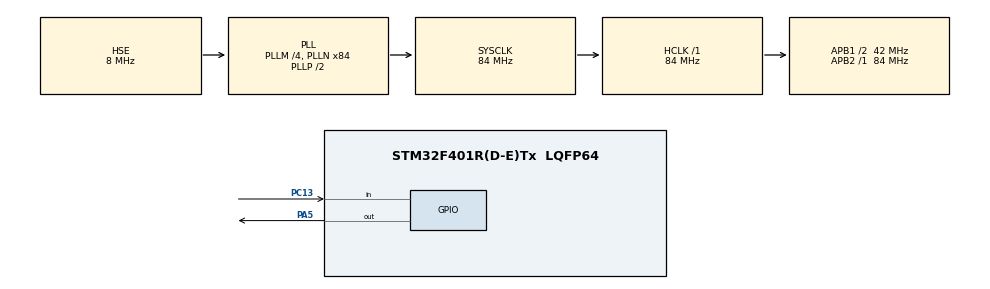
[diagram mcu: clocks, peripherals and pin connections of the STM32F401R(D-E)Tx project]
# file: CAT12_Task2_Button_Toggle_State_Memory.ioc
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Mcu.Family=STM32F4
Mcu.Name=STM32F401R(D-E)Tx
Mcu.Package=LQFP64
NVIC.PriorityGroup=NVIC_PRIORITYGROUP_4
PA13.Mode=Serial_Wire
PA13.Signal=SYS_JTMS-SWDIO
PA14.Mode=Serial_Wire
PA14.Signal=SYS_JTCK-SWCLK
PA5.Signal=GPIO_Output
PC13-ANTI_TAMP.GPIO_PuPd=GPIO_PULLUP
PC13-ANTI_TAMP.Signal=GPIO_Input
PH0\ -\ OSC_IN.Mode=HSE-External-Clock-Source
PH0\ -\ OSC_IN.Signal=RCC_OSC_IN
PH1\ -\ OSC_OUT.Mode=HSE-External-Clock-Source
PH1\ -\ OSC_OUT.Signal=RCC_OSC_OUT
ProjectManager.HeapSize=0x200
ProjectManager.StackSize=0x400
ProjectManager.TargetToolchain=STM32CubeIDE
RCC.48MHZClocksFreq_Value=42000000
RCC.AHBFreq_Value=84000000
RCC.APB1CLKDivider=RCC_HCLK_DIV2
RCC.APB1Freq_Value=42000000
RCC.APB1TimFreq_Value=84000000
RCC.APB2Freq_Value=84000000
RCC.APB2TimFreq_Value=84000000
RCC.CortexFreq_Value=84000000
RCC.HCLKFreq_Value=84000000
RCC.HSE_VALUE=8000000
RCC.HSI_VALUE=16000000
RCC.LSE_VALUE=32768
RCC.PLLM=4
RCC.PLLN=84
RCC.PLLSourceVirtual=RCC_PLLSOURCE_HSE
RCC.SYSCLKFreq_VALUE=84000000
RCC.SYSCLKSource=RCC_SYSCLKSOURCE_PLLCLK
RCC.VCOOutputFreq_Value=168000000
board=custom

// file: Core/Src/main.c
/* USER CODE BEGIN Header */
/**
  ******************************************************************************
  * @file           : main.c
  * @brief          : CAT 12 - Task 2 : B1 toggles LD2 and the LED remembers its state
  *                    Debounced press-edge detection, no blocking delays.
  ******************************************************************************
  * @attention
  *
  * Copyright (c) 2026 STMicroelectronics.
  * All rights reserved.
  *
  * This software is licensed under terms that can be found in the LICENSE file
  * in the root directory of this software component.
  * If no LICENSE file comes with this software, it is provided AS-IS.
  *
  ******************************************************************************
  */
/* USER CODE END Header */
#include "main.h"

/* USER CODE BEGIN PTD */
typedef struct
{
  uint8_t  stable;        /* debounced level, 1 = pressed */
  uint8_t  last_raw;
  uint32_t last_change;
} debounce_t;

typedef enum { BTN_NO_EVENT = 0, BTN_PRESS_EDGE, BTN_RELEASE_EDGE } btn_event_t;
/* USER CODE END PTD */

/* USER CODE BEGIN PD */
/* NUCLEO-F401RE on-board parts (UM1724)
 *   LD2 (green LED) : PA5,  ACTIVE-HIGH
 *   B1  (blue key)  : PC13, ACTIVE-LOW (external pull-up on the board)
 * Clock: 8 MHz from the ST-LINK MCO (HSE bypass) -> PLL M=4 N=84 P=2 -> 84 MHz */
#define LED_PORT          GPIOA
#define LED_PIN           GPIO_PIN_5
#define BTN_PORT          GPIOC
#define BTN_PIN           GPIO_PIN_13
#define EXPECTED_SYSCLK   84000000UL

#define DEBOUNCE_MS       30U
/* USER CODE END PD */

/* USER CODE BEGIN PV */
static debounce_t b1 = { 0 };
uint8_t  led_state   = 0;        /* the remembered LED state (0 = OFF, 1 = ON) */
uint32_t press_count = 0;
/* USER CODE END PV */

void SystemClock_Config(void);
static void MX_GPIO_Init(void);

/* USER CODE BEGIN 0 */
static inline uint8_t b1_pressed(void)
{
  return (HAL_GPIO_ReadPin(BTN_PORT, BTN_PIN) == GPIO_PIN_RESET);
}

static inline void ld2_write(uint8_t on)
{
  HAL_GPIO_WritePin(LED_PORT, LED_PIN, on ? GPIO_PIN_SET : GPIO_PIN_RESET);
}

/* Accept a new button level only after it has been stable for DEBOUNCE_MS */
static btn_event_t debounce_update(debounce_t *d, uint8_t raw, uint32_t now)
{
  if (raw != d->last_raw)
  {
    d->last_raw    = raw;
    d->last_change = now;
  }
  else if (raw != d->stable && (now - d->last_change) >= DEBOUNCE_MS)
  {
    d->stable = raw;
    return raw ? BTN_PRESS_EDGE : BTN_RELEASE_EDGE;
  }
  return BTN_NO_EVENT;
}
/* USER CODE END 0 */

int main(void)
{

  /* MCU Configuration--------------------------------------------------------*/

  /* Reset of all peripherals, Initializes the Flash interface and the Systick. */
  HAL_Init();

  /* Configure the system clock */
  SystemClock_Config();

  /* Initialize all configured peripherals */
  MX_GPIO_Init();
  /* USER CODE BEGIN 2 */
  ld2_write(led_state);
  /* USER CODE END 2 */

  /* Infinite loop */
  while (1)
  {

    /* USER CODE BEGIN 3 */
    /* Toggle on every valid press; the new state is kept in led_state, so the
     * LED stays ON/OFF after B1 is released until the next valid press.      */
    if (debounce_update(&b1, b1_pressed(), HAL_GetTick()) == BTN_PRESS_EDGE)
    {
      led_state = !led_state;
      press_count++;
      ld2_write(led_state);
    }
  }
  /* USER CODE END 3 */
}

void SystemClock_Config(void)
{
  RCC_OscInitTypeDef RCC_OscInitStruct = {0};
  RCC_ClkInitTypeDef RCC_ClkInitStruct = {0};

  /** Configure the main internal regulator output voltage
  */
  __HAL_RCC_PWR_CLK_ENABLE();
  __HAL_PWR_VOLTAGESCALING_CONFIG(PWR_REGULATOR_VOLTAGE_SCALE2);

  /** Initializes the RCC Oscillators according to the specified parameters
  * in the RCC_OscInitTypeDef structure.
  */
  RCC_OscInitStruct.OscillatorType = RCC_OSCILLATORTYPE_HSE;
  RCC_OscInitStruct.HSEState = RCC_HSE_BYPASS;
  RCC_OscInitStruct.PLL.PLLState = RCC_PLL_ON;
  RCC_OscInitStruct.PLL.PLLSource = RCC_PLLSOURCE_HSE;
  RCC_OscInitStruct.PLL.PLLM = 4;
  RCC_OscInitStruct.PLL.PLLN = 84;
  RCC_OscInitStruct.PLL.PLLP = RCC_PLLP_DIV2;
  RCC_OscInitStruct.PLL.PLLQ = 4;
  if (HAL_RCC_OscConfig(&RCC_OscInitStruct) != HAL_OK)
  {
    Error_Handler();
  }

  /** Initializes the CPU, AHB and APB buses clocks
  */
  RCC_ClkInitStruct.ClockType = RCC_CLOCKTYPE_HCLK|RCC_CLOCKTYPE_SYSCLK
                              |RCC_CLOCKTYPE_PCLK1|RCC_CLOCKTYPE_PCLK2;
  RCC_ClkInitStruct.SYSCLKSource = RCC_SYSCLKSOURCE_PLLCLK;
  RCC_ClkInitStruct.AHBCLKDivider = RCC_SYSCLK_DIV1;
  RCC_ClkInitStruct.APB1CLKDivider = RCC_HCLK_DIV2;
  RCC_ClkInitStruct.APB2CLKDivider = RCC_HCLK_DIV1;

  if (HAL_RCC_ClockConfig(&RCC_ClkInitStruct, FLASH_LATENCY_2) != HAL_OK)
  {
    Error_Handler();
  }
}

static void MX_GPIO_Init(void)
{
  GPIO_InitTypeDef GPIO_InitStruct = {0};

  /* GPIO Ports Clock Enable */
  __HAL_RCC_GPIOC_CLK_ENABLE();
  __HAL_RCC_GPIOH_CLK_ENABLE();
  __HAL_RCC_GPIOA_CLK_ENABLE();

  /*Configure GPIO pin Output Level */
  HAL_GPIO_WritePin(GPIOA, GPIO_PIN_5, GPIO_PIN_RESET);

  /*Configure GPIO pin : PC13 */
  GPIO_InitStruct.Pin = GPIO_PIN_13;
  GPIO_InitStruct.Mode = GPIO_MODE_INPUT;
  GPIO_InitStruct.Pull = GPIO_PULLUP;
  HAL_GPIO_Init(GPIOC, &GPIO_InitStruct);

  /*Configure GPIO pin : PA5 */
  GPIO_InitStruct.Pin = GPIO_PIN_5;
  GPIO_InitStruct.Mode = GPIO_MODE_OUTPUT_PP;
  GPIO_InitStruct.Pull = GPIO_NOPULL;
  GPIO_InitStruct.Speed = GPIO_SPEED_FREQ_LOW;
  HAL_GPIO_Init(GPIOA, &GPIO_InitStruct);

}

void Error_Handler(void)
{
  __disable_irq();
  while (1)
  {
  }
}
